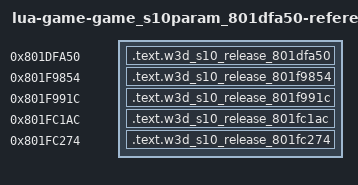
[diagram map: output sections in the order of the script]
/* Generated reference-only placements. All bodies are source-built. */
OUTPUT_FORMAT("elf32-powerpc")
OUTPUT_ARCH(powerpc)
ENTRY(w3d_s10_release_801dfa50)
_SDA_BASE_ = 0x804b2540;
_SDA2_BASE_ = 0x804c2540;
fn_801e0a5c = 0x801e0a5c;
fn_801e107c = 0x801e107c;
fn_801f96f4 = 0x801f96f4;
fn_801f97a4 = 0x801f97a4;
fn_801fa11c = 0x801fa11c;
fn_801fb6a4 = 0x801fb6a4;
fn_801fc04c = 0x801fc04c;
fn_801fc0fc = 0x801fc0fc;
fn_801fc428 = 0x801fc428;
fn_801fc564 = 0x801fc564;
SECTIONS {
  .text.w3d_s10_release_801dfa50 0x801dfa50 : { *(.text.w3d_s10_release_801dfa50) }
  .text.w3d_s10_release_801f9854 0x801f9854 : { *(.text.w3d_s10_release_801f9854) }
  .text.w3d_s10_release_801f991c 0x801f991c : { *(.text.w3d_s10_release_801f991c) }
  .text.w3d_s10_release_801fc1ac 0x801fc1ac : { *(.text.w3d_s10_release_801fc1ac) }
  .text.w3d_s10_release_801fc274 0x801fc274 : { *(.text.w3d_s10_release_801fc274) }
  /DISCARD/ : { *(.text*) *(.rodata*) *(.data*) *(.bss*) *(.sdata*) *(.sbss*) *(.comment) }
}
